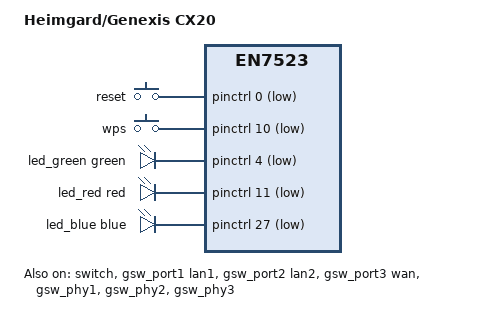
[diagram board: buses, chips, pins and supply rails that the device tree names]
/* SPDX-License-Identifier: GPL-2.0-or-later OR MIT */
/dts-v1/;

#include "en7523-genexis.dtsi"

/ {
	model = "Heimgard/Genexis CX20";
	compatible = "genexis,arcee", "airoha,en7523";

	aliases {
		led-boot = &led_red;
		led-failsafe = &led_red;
		led-upgrade = &led_blue;
		led-running = &led_green;
	};

	keys {
		compatible = "gpio-keys-polled";
		poll-interval = <100>;

		reset {
			label = "reset";
			linux,code = <KEY_RESTART>;
			gpios = <&pinctrl 0 GPIO_ACTIVE_LOW>;
			debounce-interval = <60>;
		};

		wps {
			label = "wps";
			linux,code = <KEY_WPS_BUTTON>;
			gpios = <&pinctrl 10 GPIO_ACTIVE_LOW>;
			debounce-interval = <60>;
		};
	};

	leds {
		compatible = "gpio-leds";

		led_green: led@4 {
			color = <LED_COLOR_ID_GREEN>;
			function = LED_FUNCTION_STATUS;
			function-enumerator = <4>;
			gpios = <&pinctrl 4 GPIO_ACTIVE_LOW>;
		};

		led_red: led@11 {
			color = <LED_COLOR_ID_RED>;
			function = LED_FUNCTION_STATUS;
			function-enumerator = <11>;
			gpios = <&pinctrl 11 GPIO_ACTIVE_LOW>;
		};

		led_blue: led@27 {
			color = <LED_COLOR_ID_BLUE>;
			function = LED_FUNCTION_STATUS;
			function-enumerator = <27>;
			gpios = <&pinctrl 27 GPIO_ACTIVE_LOW>;
		};
	};
};

&switch {
	status = "okay";
};

&gsw_port1 {
	label = "lan1";
	status = "okay";
};

&gsw_port2 {
	label = "lan2";
	status = "okay";
};

&gsw_port3 {
	label = "wan";
	status = "okay";
};

&gsw_phy1 {
	status = "okay";
};

&gsw_phy2 {
	status = "okay";
};

&gsw_phy3 {
	status = "okay";
};
